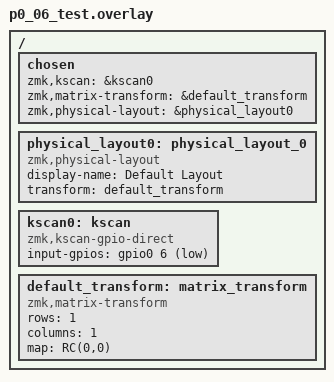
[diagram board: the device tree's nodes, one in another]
#include <dt-bindings/zmk/matrix_transform.h>

/ {
    chosen {
        zmk,kscan = &kscan0;
        zmk,matrix-transform = &default_transform;
        zmk,physical-layout = &physical_layout0;
    };

    physical_layout0: physical_layout_0 {
        compatible = "zmk,physical-layout";
        display-name = "Default Layout";
        transform = <&default_transform>;
    };

    kscan0: kscan {
        compatible = "zmk,kscan-gpio-direct";
        input-gpios = <&gpio0 6 (GPIO_ACTIVE_LOW | GPIO_PULL_UP)>;
    };

    default_transform: matrix_transform {
        compatible = "zmk,matrix-transform";
        rows = <1>;
        columns = <1>;
        map = <RC(0,0)>;
    };
};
